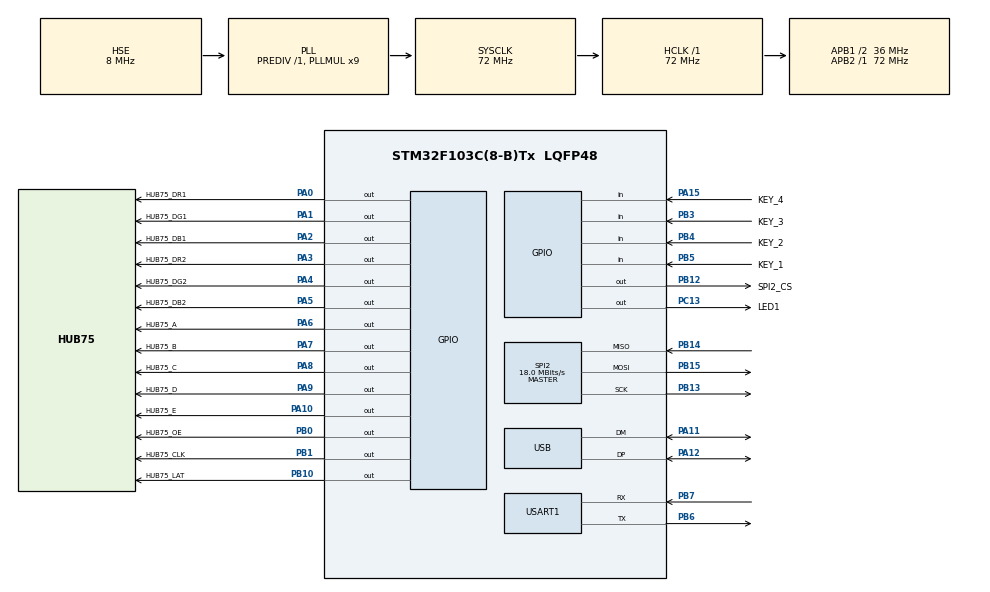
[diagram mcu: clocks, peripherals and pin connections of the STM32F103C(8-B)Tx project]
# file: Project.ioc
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Mcu.Family=STM32F1
Mcu.Name=STM32F103C(8-B)Tx
Mcu.Package=LQFP48
NVIC.PriorityGroup=NVIC_PRIORITYGROUP_4
NVIC.TIM2_IRQn=true\:1\:0\:true\:false\:true\:true\:true\:true
NVIC.USART1_IRQn=true\:3\:0\:true\:false\:true\:true\:true\:true
PA0-WKUP.GPIO_Label=HUB75_DR1
PA0-WKUP.Signal=GPIO_Output
PA1.GPIO_Label=HUB75_DG1
PA1.Signal=GPIO_Output
PA10.GPIO_Label=HUB75_E
PA10.Signal=GPIO_Output
PA11.Mode=Device
PA11.Signal=USB_DM
PA12.Mode=Device
PA12.Signal=USB_DP
PA13.Mode=Serial_Wire
PA13.Signal=SYS_JTMS-SWDIO
PA14.Mode=Serial_Wire
PA14.Signal=SYS_JTCK-SWCLK
PA15.GPIO_Label=KEY_4
PA15.Signal=GPIO_Input
PA2.GPIO_Label=HUB75_DB1
PA2.Signal=GPIO_Output
PA3.GPIO_Label=HUB75_DR2
PA3.Signal=GPIO_Output
PA4.GPIO_Label=HUB75_DG2
PA4.Signal=GPIO_Output
PA5.GPIO_Label=HUB75_DB2
PA5.Signal=GPIO_Output
PA6.GPIO_Label=HUB75_A
PA6.Signal=GPIO_Output
PA7.GPIO_Label=HUB75_B
PA7.Signal=GPIO_Output
PA8.GPIO_Label=HUB75_C
PA8.Signal=GPIO_Output
PA9.GPIO_Label=HUB75_D
PA9.Signal=GPIO_Output
PB0.GPIO_Label=HUB75_OE
PB0.Signal=GPIO_Output
PB1.GPIO_Label=HUB75_CLK
PB1.Signal=GPIO_Output
PB10.GPIO_Label=HUB75_LAT
PB10.Signal=GPIO_Output
PB12.GPIO_Label=SPI2_CS
PB12.GPIO_Speed=GPIO_SPEED_FREQ_HIGH
PB12.PinState=GPIO_PIN_SET
PB12.Signal=GPIO_Output
PB13.Mode=Full_Duplex_Master
PB13.Signal=SPI2_SCK
PB14.Mode=Full_Duplex_Master
PB14.Signal=SPI2_MISO
PB15.Mode=Full_Duplex_Master
PB15.Signal=SPI2_MOSI
PB3.GPIO_Label=KEY_3
PB3.Signal=GPIO_Input
PB4.GPIO_Label=KEY_2
PB4.Signal=GPIO_Input
PB5.GPIO_Label=KEY_1
PB5.Signal=GPIO_Input
PB6.Mode=Asynchronous
PB6.Signal=USART1_TX
PB7.Mode=Asynchronous
PB7.Signal=USART1_RX
PC13-TAMPER-RTC.GPIO_Label=LED1
PC13-TAMPER-RTC.Signal=GPIO_Output
PC14-OSC32_IN.Mode=LSE-External-Oscillator
PC14-OSC32_IN.Signal=RCC_OSC32_IN
PC15-OSC32_OUT.Mode=LSE-External-Oscillator
PC15-OSC32_OUT.Signal=RCC_OSC32_OUT
PD0-OSC_IN.Mode=HSE-External-Oscillator
PD0-OSC_IN.Signal=RCC_OSC_IN
PD1-OSC_OUT.Mode=HSE-External-Oscillator
PD1-OSC_OUT.Signal=RCC_OSC_OUT
ProjectManager.HeapSize=0x400
ProjectManager.StackSize=0x800
ProjectManager.TargetToolchain=EWARM V7
RCC.AHBFreq_Value=72000000
RCC.APB1CLKDivider=RCC_HCLK_DIV2
RCC.APB1Freq_Value=36000000
RCC.APB1TimFreq_Value=72000000
RCC.APB2Freq_Value=72000000
RCC.APB2TimFreq_Value=72000000
RCC.HCLKFreq_Value=72000000
RCC.PLLMUL=RCC_PLL_MUL9
RCC.PLLSourceVirtual=RCC_PLLSOURCE_HSE
RCC.RTCClockSelection=RCC_RTCCLKSOURCE_LSE
RCC.SYSCLKFreq_VALUE=72000000
RCC.SYSCLKSource=RCC_SYSCLKSOURCE_PLLCLK
RCC.USBFreq_Value=48000000
RCC.USBPrescaler=RCC_USBCLKSOURCE_PLL_DIV1_5
SPI2.CLKPhase=SPI_PHASE_1EDGE
SPI2.CLKPolarity=SPI_POLARITY_LOW
SPI2.CalculateBaudRate=18.0 MBits/s
SPI2.Direction=SPI_DIRECTION_2LINES
SPI2.Mode=SPI_MODE_MASTER
SPI2.VirtualType=VM_MASTER
TIM2.Period=4
TIM2.Prescaler=499
USART1.VirtualMode=VM_ASYNC
VP_CRC_VS_CRC.Mode=CRC_Activate
VP_RTC_No_RTC_Output.Mode=RTC_OUT_NO
VP_RTC_VS_RTC_Activate.Mode=RTC_Enabled
VP_TIM2_VS_ClockSourceINT.Mode=Internal
board=custom

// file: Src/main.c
/* USER CODE BEGIN Header */
/**
  ******************************************************************************
  * @file           : main.c
  * @brief          : Main program body
  ******************************************************************************
  * @attention
  *
  * <h2><center>&copy; Copyright (c) 2020 STMicroelectronics.
  * All rights reserved.</center></h2>
  *
  * This software component is licensed by ST under BSD 3-Clause license,
  * the "License"; You may not use this file except in compliance with the
  * License. You may obtain a copy of the License at:
  *                        opensource.org/licenses/BSD-3-Clause
  *
  ******************************************************************************
  */
/* USER CODE END Header */
#include "main.h"

/* USER CODE BEGIN Includes */
#include "includes.h"
/* USER CODE END Includes */

CRC_HandleTypeDef hcrc;

RTC_HandleTypeDef hrtc;

SPI_HandleTypeDef hspi2;

TIM_HandleTypeDef htim2;

UART_HandleTypeDef huart1, huart2, huart3;

PCD_HandleTypeDef hpcd_USB_FS;

void SystemClock_Config(void);
static void MX_RTC_Init(void);
static void MX_TIM2_Init(void);
static void MX_CRC_Init(void);
static void MX_GPIO_Init(void);
static void MX_USART1_UART_Init(void);
static void MX_SPI2_Init(void);
static void MX_USB_PCD_Init(void);

int main(void)
{

  /* MCU Configuration--------------------------------------------------------*/

  /* Reset of all peripherals, Initializes the Flash interface and the Systick. */
  HAL_Init();

  /* Configure the system clock */
  SystemClock_Config();

  /* Initialize all configured peripherals */
  MX_RTC_Init();
  MX_TIM2_Init();
  MX_CRC_Init();
  MX_GPIO_Init();
  MX_USART1_UART_Init();
  MX_SPI2_Init();
  MX_USB_PCD_Init();
  /* USER CODE BEGIN 2 */
  api_uart_init();
  bsp_hub75_init();
  apl_sys_data_read();
  apl_menu_init();
  api_tim_start();
  Task_Start();
  /* USER CODE END 2 */

  /* Infinite loop */
  while (1)
  {

    /* USER CODE BEGIN 3 */
    Task_Handle();
    Task_MatrixDisplay();
  }
  /* USER CODE END 3 */
}

void SystemClock_Config(void)
{
  RCC_OscInitTypeDef RCC_OscInitStruct = {0};
  RCC_ClkInitTypeDef RCC_ClkInitStruct = {0};
  RCC_PeriphCLKInitTypeDef PeriphClkInit = {0};

  /** Initializes the RCC Oscillators according to the specified parameters
  * in the RCC_OscInitTypeDef structure.
  */
  RCC_OscInitStruct.OscillatorType = RCC_OSCILLATORTYPE_HSE|RCC_OSCILLATORTYPE_LSE;
  RCC_OscInitStruct.HSEState = RCC_HSE_ON;
  RCC_OscInitStruct.HSEPredivValue = RCC_HSE_PREDIV_DIV1;
  RCC_OscInitStruct.LSEState = RCC_LSE_ON;
  RCC_OscInitStruct.HSIState = RCC_HSI_ON;
  RCC_OscInitStruct.PLL.PLLState = RCC_PLL_ON;
  RCC_OscInitStruct.PLL.PLLSource = RCC_PLLSOURCE_HSE;
  RCC_OscInitStruct.PLL.PLLMUL = RCC_PLL_MUL9;
  if (HAL_RCC_OscConfig(&RCC_OscInitStruct) != HAL_OK)
  {
    Error_Handler();
  }

  /** Initializes the CPU, AHB and APB buses clocks
  */
  RCC_ClkInitStruct.ClockType = RCC_CLOCKTYPE_HCLK|RCC_CLOCKTYPE_SYSCLK
                              |RCC_CLOCKTYPE_PCLK1|RCC_CLOCKTYPE_PCLK2;
  RCC_ClkInitStruct.SYSCLKSource = RCC_SYSCLKSOURCE_PLLCLK;
  RCC_ClkInitStruct.AHBCLKDivider = RCC_SYSCLK_DIV1;
  RCC_ClkInitStruct.APB1CLKDivider = RCC_HCLK_DIV2;
  RCC_ClkInitStruct.APB2CLKDivider = RCC_HCLK_DIV1;

  if (HAL_RCC_ClockConfig(&RCC_ClkInitStruct, FLASH_LATENCY_2) != HAL_OK)
  {
    Error_Handler();
  }
  PeriphClkInit.PeriphClockSelection = RCC_PERIPHCLK_RTC|RCC_PERIPHCLK_USB;
  PeriphClkInit.RTCClockSelection = RCC_RTCCLKSOURCE_LSE;
  PeriphClkInit.UsbClockSelection = RCC_USBCLKSOURCE_PLL_DIV1_5;
  if (HAL_RCCEx_PeriphCLKConfig(&PeriphClkInit) != HAL_OK)
  {
    Error_Handler();
  }
}

static void MX_CRC_Init(void)
{

  hcrc.Instance = CRC;
  if (HAL_CRC_Init(&hcrc) != HAL_OK)
  {
    Error_Handler();
  }

}

static void MX_RTC_Init(void)
{

  RTC_TimeTypeDef sTime = {0};
  RTC_DateTypeDef DateToUpdate = {0};

  /** Initialize RTC Only
  */
  hrtc.Instance = RTC;
  hrtc.Init.AsynchPrediv = RTC_AUTO_1_SECOND;
  hrtc.Init.OutPut = RTC_OUTPUTSOURCE_NONE;
  if (HAL_RTC_Init(&hrtc) != HAL_OK)
  {
    Error_Handler();
  }

  /** Initialize RTC and set the Time and Date
  */
  sTime.Hours = 0x0;
  sTime.Minutes = 0x0;
  sTime.Seconds = 0x0;

  if (HAL_RTC_SetTime(&hrtc, &sTime, RTC_FORMAT_BCD) != HAL_OK)
  {
    Error_Handler();
  }
  DateToUpdate.WeekDay = RTC_WEEKDAY_MONDAY;
  DateToUpdate.Month = RTC_MONTH_JANUARY;
  DateToUpdate.Date = 0x1;
  DateToUpdate.Year = 0x0;

  if (HAL_RTC_SetDate(&hrtc, &DateToUpdate, RTC_FORMAT_BCD) != HAL_OK)
  {
    Error_Handler();
  }

}

static void MX_SPI2_Init(void)
{

  /* SPI2 parameter configuration*/
  hspi2.Instance = SPI2;
  hspi2.Init.Mode = SPI_MODE_MASTER;
  hspi2.Init.Direction = SPI_DIRECTION_2LINES;
  hspi2.Init.DataSize = SPI_DATASIZE_8BIT;
  hspi2.Init.CLKPolarity = SPI_POLARITY_LOW;
  hspi2.Init.CLKPhase = SPI_PHASE_1EDGE;
  hspi2.Init.NSS = SPI_NSS_SOFT;
  hspi2.Init.BaudRatePrescaler = SPI_BAUDRATEPRESCALER_2;
  hspi2.Init.FirstBit = SPI_FIRSTBIT_MSB;
  hspi2.Init.TIMode = SPI_TIMODE_DISABLE;
  hspi2.Init.CRCCalculation = SPI_CRCCALCULATION_DISABLE;
  hspi2.Init.CRCPolynomial = 10;
  if (HAL_SPI_Init(&hspi2) != HAL_OK)
  {
    Error_Handler();
  }

}

static void MX_TIM2_Init(void)
{

  TIM_ClockConfigTypeDef sClockSourceConfig = {0};
  TIM_MasterConfigTypeDef sMasterConfig = {0};

  htim2.Instance = TIM2;
  htim2.Init.Prescaler = 499;
  htim2.Init.CounterMode = TIM_COUNTERMODE_UP;
  htim2.Init.Period = 4;
  htim2.Init.ClockDivision = TIM_CLOCKDIVISION_DIV1;
  htim2.Init.AutoReloadPreload = TIM_AUTORELOAD_PRELOAD_DISABLE;
  if (HAL_TIM_Base_Init(&htim2) != HAL_OK)
  {
    Error_Handler();
  }
  sClockSourceConfig.ClockSource = TIM_CLOCKSOURCE_INTERNAL;
  if (HAL_TIM_ConfigClockSource(&htim2, &sClockSourceConfig) != HAL_OK)
  {
    Error_Handler();
  }
  sMasterConfig.MasterOutputTrigger = TIM_TRGO_RESET;
  sMasterConfig.MasterSlaveMode = TIM_MASTERSLAVEMODE_DISABLE;
  if (HAL_TIMEx_MasterConfigSynchronization(&htim2, &sMasterConfig) != HAL_OK)
  {
    Error_Handler();
  }

}

static void MX_USART1_UART_Init(void)
{

  huart1.Instance = USART1;
  huart1.Init.BaudRate = 115200;
  huart1.Init.WordLength = UART_WORDLENGTH_8B;
  huart1.Init.StopBits = UART_STOPBITS_1;
  huart1.Init.Parity = UART_PARITY_NONE;
  huart1.Init.Mode = UART_MODE_TX_RX;
  huart1.Init.HwFlowCtl = UART_HWCONTROL_NONE;
  huart1.Init.OverSampling = UART_OVERSAMPLING_16;
  if (HAL_UART_Init(&huart1) != HAL_OK)
  {
    Error_Handler();
  }

}

static void MX_USB_PCD_Init(void)
{

  hpcd_USB_FS.Instance = USB;
  hpcd_USB_FS.Init.dev_endpoints = 8;
  hpcd_USB_FS.Init.speed = PCD_SPEED_FULL;
  hpcd_USB_FS.Init.low_power_enable = DISABLE;
  hpcd_USB_FS.Init.lpm_enable = DISABLE;
  hpcd_USB_FS.Init.battery_charging_enable = DISABLE;
  if (HAL_PCD_Init(&hpcd_USB_FS) != HAL_OK)
  {
    Error_Handler();
  }

}

static void MX_GPIO_Init(void)
{
  GPIO_InitTypeDef GPIO_InitStruct = {0};

  /* GPIO Ports Clock Enable */
  __HAL_RCC_GPIOC_CLK_ENABLE();
  __HAL_RCC_GPIOD_CLK_ENABLE();
  __HAL_RCC_GPIOA_CLK_ENABLE();
  __HAL_RCC_GPIOB_CLK_ENABLE();

  /*Configure GPIO pin Output Level */
  HAL_GPIO_WritePin(LED1_GPIO_Port, LED1_Pin, GPIO_PIN_RESET);

  /*Configure GPIO pin Output Level */
  HAL_GPIO_WritePin(GPIOA, HUB75_DR1_Pin|HUB75_DG1_Pin|HUB75_DB1_Pin|HUB75_DR2_Pin
                          |HUB75_DG2_Pin|HUB75_DB2_Pin|HUB75_A_Pin|HUB75_B_Pin
                          |HUB75_C_Pin|HUB75_D_Pin|HUB75_E_Pin, GPIO_PIN_RESET);

  /*Configure GPIO pin Output Level */
  HAL_GPIO_WritePin(GPIOB, HUB75_OE_Pin|HUB75_CLK_Pin|HUB75_LAT_Pin, GPIO_PIN_RESET);

  /*Configure GPIO pin Output Level */
  HAL_GPIO_WritePin(SPI2_CS_GPIO_Port, SPI2_CS_Pin, GPIO_PIN_SET);

  /*Configure GPIO pin : LED1_Pin */
  GPIO_InitStruct.Pin = LED1_Pin;
  GPIO_InitStruct.Mode = GPIO_MODE_OUTPUT_PP;
  GPIO_InitStruct.Pull = GPIO_NOPULL;
  GPIO_InitStruct.Speed = GPIO_SPEED_FREQ_LOW;
  HAL_GPIO_Init(LED1_GPIO_Port, &GPIO_InitStruct);

  /*Configure GPIO pins : HUB75_DR1_Pin HUB75_DG1_Pin HUB75_DB1_Pin HUB75_DR2_Pin
                           HUB75_DG2_Pin HUB75_DB2_Pin HUB75_A_Pin HUB75_B_Pin
                           HUB75_C_Pin HUB75_D_Pin HUB75_E_Pin */
  GPIO_InitStruct.Pin = HUB75_DR1_Pin|HUB75_DG1_Pin|HUB75_DB1_Pin|HUB75_DR2_Pin
                          |HUB75_DG2_Pin|HUB75_DB2_Pin|HUB75_A_Pin|HUB75_B_Pin
                          |HUB75_C_Pin|HUB75_D_Pin|HUB75_E_Pin;
  GPIO_InitStruct.Mode = GPIO_MODE_OUTPUT_PP;
  GPIO_InitStruct.Pull = GPIO_NOPULL;
  GPIO_InitStruct.Speed = GPIO_SPEED_FREQ_LOW;
  HAL_GPIO_Init(GPIOA, &GPIO_InitStruct);

  /*Configure GPIO pins : HUB75_OE_Pin HUB75_CLK_Pin HUB75_LAT_Pin */
  GPIO_InitStruct.Pin = HUB75_OE_Pin|HUB75_CLK_Pin|HUB75_LAT_Pin;
  GPIO_InitStruct.Mode = GPIO_MODE_OUTPUT_PP;
  GPIO_InitStruct.Pull = GPIO_NOPULL;
  GPIO_InitStruct.Speed = GPIO_SPEED_FREQ_LOW;
  HAL_GPIO_Init(GPIOB, &GPIO_InitStruct);

  /*Configure GPIO pins : PB2 PB11 PB8 PB9 */
  GPIO_InitStruct.Pin = GPIO_PIN_2|GPIO_PIN_11|GPIO_PIN_8|GPIO_PIN_9;
  GPIO_InitStruct.Mode = GPIO_MODE_ANALOG;
  HAL_GPIO_Init(GPIOB, &GPIO_InitStruct);

  /*Configure GPIO pin : SPI2_CS_Pin */
  GPIO_InitStruct.Pin = SPI2_CS_Pin;
  GPIO_InitStruct.Mode = GPIO_MODE_OUTPUT_PP;
  GPIO_InitStruct.Pull = GPIO_NOPULL;
  GPIO_InitStruct.Speed = GPIO_SPEED_FREQ_HIGH;
  HAL_GPIO_Init(SPI2_CS_GPIO_Port, &GPIO_InitStruct);

  /*Configure GPIO pin : KEY_4_Pin */
  GPIO_InitStruct.Pin = KEY_4_Pin;
  GPIO_InitStruct.Mode = GPIO_MODE_INPUT;
  GPIO_InitStruct.Pull = GPIO_NOPULL;
  HAL_GPIO_Init(KEY_4_GPIO_Port, &GPIO_InitStruct);

  /*Configure GPIO pins : KEY_3_Pin KEY_2_Pin KEY_1_Pin */
  GPIO_InitStruct.Pin = KEY_3_Pin|KEY_2_Pin|KEY_1_Pin;
  GPIO_InitStruct.Mode = GPIO_MODE_INPUT;
  GPIO_InitStruct.Pull = GPIO_NOPULL;
  HAL_GPIO_Init(GPIOB, &GPIO_InitStruct);

}

void Error_Handler(void)
{
}
